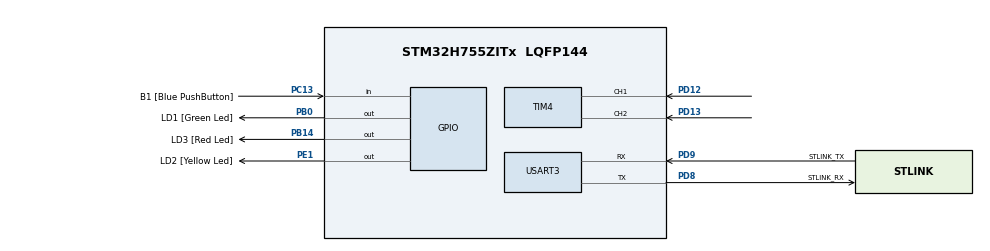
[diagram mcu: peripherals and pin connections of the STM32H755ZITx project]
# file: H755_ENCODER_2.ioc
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CortexM4.IPs=FATFS_M4\:I,FREERTOS_M4\:I,IWDG2\:I,RCC,WWDG2\:I,DMA,BDMA,MDMA,NVIC2\:I,ETH,USART3,DEBUG,USB_DEVICE_M4\:I,USB_HOST_M4\:I,PDM2PCM_M4\:I,PWR,RESMGR_UTILITY,SYS_M4\:I,CORTEX_M4\:I,OPENAMP_M4\:I,VREFBUF,GPIO
CortexM7.IPs=FATFS_M7\:I,FREERTOS_M7\:I,IWDG1\:I,RCC\:I,WWDG1\:I,DMA\:I,BDMA\:I,MDMA\:I,NVIC1\:I,ETH\:I,USART3\:I,USB_OTG_FS\:I,SYS\:I,CORTEX_M7\:I,DEBUG\:I,USB_DEVICE_M7\:I,USB_HOST_M7\:I,PDM2PCM_M7\:I,PWR\:I,RESMGR_UTILITY\:I,OPENAMP_M7\:I,VREFBUF\:I,GPIO\:I,TIM4\:I
Mcu.Family=STM32H7
Mcu.Name=STM32H755ZITx
Mcu.Package=LQFP144
NVIC1.PriorityGroup=NVIC_PRIORITYGROUP_4
NVIC1.TIM4_IRQn=true\:0\:0\:false\:false\:true\:true\:true\:true
NVIC2.PriorityGroup=NVIC_PRIORITYGROUP_4
PB0.GPIO_Label=LD1 [Green Led]
PB0.PinAttribute=Free
PB0.Signal=GPIO_Output
PB14.GPIO_Label=LD3 [Red Led]
PB14.PinAttribute=Free
PB14.Signal=GPIO_Output
PC13.GPIO_Label=B1 [Blue PushButton]
PC13.PinAttribute=Free
PC13.Signal=GPIO_Input
PC14-OSC32_IN\ (OSC32_IN).Mode=LSE-External-Oscillator
PC14-OSC32_IN\ (OSC32_IN).PinAttribute=CortexM7
PC14-OSC32_IN\ (OSC32_IN).Signal=RCC_OSC32_IN
PC15-OSC32_OUT\ (OSC32_OUT).Mode=LSE-External-Oscillator
PC15-OSC32_OUT\ (OSC32_OUT).PinAttribute=CortexM7
PC15-OSC32_OUT\ (OSC32_OUT).Signal=RCC_OSC32_OUT
PD12.PinAttribute=CortexM7
PD12.Signal=S_TIM4_CH1
PD13.PinAttribute=CortexM7
PD13.Signal=S_TIM4_CH2
PD8.GPIO_Label=STLINK_RX
PD8.Mode=Asynchronous
PD8.PinAttribute=CortexM7
PD8.Signal=USART3_TX
PD9.GPIO_Label=STLINK_TX
PD9.Mode=Asynchronous
PD9.PinAttribute=CortexM7
PD9.Signal=USART3_RX
PE1.GPIO_Label=LD2 [Yellow Led]
PE1.PinAttribute=Free
PE1.Signal=GPIO_Output
PH0-OSC_IN\ (PH0).Mode=HSE-External-Clock-Source
PH0-OSC_IN\ (PH0).PinAttribute=CortexM7
PH0-OSC_IN\ (PH0).Signal=RCC_OSC_IN
ProjectManager.HeapSize=M4-0x200,M7-0x200
ProjectManager.StackSize=M4-0x400,M7-0x400
ProjectManager.TargetToolchain=STM32CubeIDE
RCC.ADCFreq_Value=16125000
RCC.APB1Freq_Value=64000000
RCC.APB2Freq_Value=64000000
RCC.APB3Freq_Value=64000000
RCC.APB4Freq_Value=64000000
RCC.CortexFreq_Value=64000000
RCC.DIVM1=1
RCC.DIVN1=24
RCC.DIVQ1=4
RCC.HCLKFreq_Value=64000000
RCC.HSE_VALUE=8000000
RCC.PLL2FRACN=0
RCC.PLL3FRACN=0
RCC.PLLFRACN=0
RCC.PLLSourceVirtual=RCC_PLLSOURCE_HSE
RCC.PWR_Regulator_Voltage_Scale=PWR_REGULATOR_VOLTAGE_SCALE2
RCC.SYSCLKFreq_VALUE=64000000
RCC.SupplySource=PWR_DIRECT_SMPS_SUPPLY
RCC.USBFreq_Value=48000000
SH.S_TIM4_CH1.0=TIM4_CH1,Encoder_Interface
SH.S_TIM4_CH2.0=TIM4_CH2,Encoder_Interface
TIM4.EncoderMode=TIM_ENCODERMODE_TI12
TIM4.IC1Filter=10
TIM4.IC1Polarity=TIM_ICPOLARITY_FALLING
TIM4.IC2Filter=10
TIM4.IC2Polarity=TIM_ICPOLARITY_FALLING
USART3.VirtualMode-Asynchronous=VM_ASYNC
VP_SYS_M4_VS_Systick.Mode=SysTick
board=NUCLEO-H755ZI-Q

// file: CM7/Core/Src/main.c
/* USER CODE BEGIN Header */
/**
  ******************************************************************************
  * @file           : main.c
  * @brief          : Main program body
  ******************************************************************************
  * @attention
  *
  * Copyright (c) 2023 STMicroelectronics.
  * All rights reserved.
  *
  * This software is licensed under terms that can be found in the LICENSE file
  * in the root directory of this software component.
  * If no LICENSE file comes with this software, it is provided AS-IS.
  *
  ******************************************************************************
  */
/* USER CODE END Header */
#include "main.h"

/* USER CODE BEGIN Includes */
#include "myprintf.h"
/* USER CODE END Includes */

/* USER CODE BEGIN PD */

#ifndef HSEM_ID_0
#define HSEM_ID_0 (0U) /* HW semaphore 0*/
#endif
/* USER CODE END PD */

TIM_HandleTypeDef htim4;

UART_HandleTypeDef huart3;

void SystemClock_Config(void);
static void MX_GPIO_Init(void);
static void MX_USART3_UART_Init(void);
static void MX_TIM4_Init(void);

/* USER CODE BEGIN 0 */

uint32_t timer_counter = 0;
int16_t counter = 0;
void HAL_TIM_IC_CaptureCallback(TIM_HandleTypeDef *htim){
	timer_counter = __HAL_TIM_GET_COUNTER(&htim4);
	counter = (int16_t)timer_counter;
}
/* USER CODE END 0 */

int main(void)
{
/* USER CODE BEGIN Boot_Mode_Sequence_0 */
  int32_t timeout;
/* USER CODE END Boot_Mode_Sequence_0 */

/* USER CODE BEGIN Boot_Mode_Sequence_1 */
  /* Wait until CPU2 boots and enters in stop mode or timeout*/
  timeout = 0xFFFF;
  while((__HAL_RCC_GET_FLAG(RCC_FLAG_D2CKRDY) != RESET) && (timeout-- > 0));
  if ( timeout < 0 )
  {
  Error_Handler();
  }
/* USER CODE END Boot_Mode_Sequence_1 */
  /* MCU Configuration--------------------------------------------------------*/

  /* Reset of all peripherals, Initializes the Flash interface and the Systick. */
  HAL_Init();

  /* Configure the system clock */
  SystemClock_Config();
/* USER CODE BEGIN Boot_Mode_Sequence_2 */
/* When system initialization is finished, Cortex-M7 will release Cortex-M4 by means of
HSEM notification */
/*HW semaphore Clock enable*/
__HAL_RCC_HSEM_CLK_ENABLE();
/*Take HSEM */
HAL_HSEM_FastTake(HSEM_ID_0);
/*Release HSEM in order to notify the CPU2(CM4)*/
HAL_HSEM_Release(HSEM_ID_0,0);
/* wait until CPU2 wakes up from stop mode */
timeout = 0xFFFF;
while((__HAL_RCC_GET_FLAG(RCC_FLAG_D2CKRDY) == RESET) && (timeout-- > 0));
if ( timeout < 0 )
{
Error_Handler();
}
/* USER CODE END Boot_Mode_Sequence_2 */

  /* Initialize all configured peripherals */
  MX_GPIO_Init();
  MX_USART3_UART_Init();
  MX_TIM4_Init();

  /* Infinite loop */
  while (1)
  {

    /* USER CODE BEGIN 3 */
	  //1100 ticks per turn approximately
	  //Diameter 62mm
	  //Circumference 195mm
	  printf("%f %d \r\n", ((float)timer_counter/1100)*19.5, counter);

  }
  /* USER CODE END 3 */
}

void SystemClock_Config(void)
{
  RCC_OscInitTypeDef RCC_OscInitStruct = {0};
  RCC_ClkInitTypeDef RCC_ClkInitStruct = {0};

  /** Supply configuration update enable
  */
  HAL_PWREx_ConfigSupply(PWR_DIRECT_SMPS_SUPPLY);

  /** Configure the main internal regulator output voltage
  */
  __HAL_PWR_VOLTAGESCALING_CONFIG(PWR_REGULATOR_VOLTAGE_SCALE2);

  while(!__HAL_PWR_GET_FLAG(PWR_FLAG_VOSRDY)) {}

  /** Initializes the RCC Oscillators according to the specified parameters
  * in the RCC_OscInitTypeDef structure.
  */
  RCC_OscInitStruct.OscillatorType = RCC_OSCILLATORTYPE_HSI;
  RCC_OscInitStruct.HSIState = RCC_HSI_DIV1;
  RCC_OscInitStruct.HSICalibrationValue = RCC_HSICALIBRATION_DEFAULT;
  RCC_OscInitStruct.PLL.PLLState = RCC_PLL_NONE;
  if (HAL_RCC_OscConfig(&RCC_OscInitStruct) != HAL_OK)
  {
    Error_Handler();
  }

  /** Initializes the CPU, AHB and APB buses clocks
  */
  RCC_ClkInitStruct.ClockType = RCC_CLOCKTYPE_HCLK|RCC_CLOCKTYPE_SYSCLK
                              |RCC_CLOCKTYPE_PCLK1|RCC_CLOCKTYPE_PCLK2
                              |RCC_CLOCKTYPE_D3PCLK1|RCC_CLOCKTYPE_D1PCLK1;
  RCC_ClkInitStruct.SYSCLKSource = RCC_SYSCLKSOURCE_HSI;
  RCC_ClkInitStruct.SYSCLKDivider = RCC_SYSCLK_DIV1;
  RCC_ClkInitStruct.AHBCLKDivider = RCC_HCLK_DIV1;
  RCC_ClkInitStruct.APB3CLKDivider = RCC_APB3_DIV1;
  RCC_ClkInitStruct.APB1CLKDivider = RCC_APB1_DIV1;
  RCC_ClkInitStruct.APB2CLKDivider = RCC_APB2_DIV1;
  RCC_ClkInitStruct.APB4CLKDivider = RCC_APB4_DIV1;

  if (HAL_RCC_ClockConfig(&RCC_ClkInitStruct, FLASH_LATENCY_1) != HAL_OK)
  {
    Error_Handler();
  }
}

static void MX_TIM4_Init(void)
{

  TIM_Encoder_InitTypeDef sConfig = {0};
  TIM_MasterConfigTypeDef sMasterConfig = {0};

  htim4.Instance = TIM4;
  htim4.Init.Prescaler = 0;
  htim4.Init.CounterMode = TIM_COUNTERMODE_UP;
  htim4.Init.Period = 65535;
  htim4.Init.ClockDivision = TIM_CLOCKDIVISION_DIV1;
  htim4.Init.AutoReloadPreload = TIM_AUTORELOAD_PRELOAD_DISABLE;
  sConfig.EncoderMode = TIM_ENCODERMODE_TI12;
  sConfig.IC1Polarity = TIM_ICPOLARITY_FALLING;
  sConfig.IC1Selection = TIM_ICSELECTION_DIRECTTI;
  sConfig.IC1Prescaler = TIM_ICPSC_DIV1;
  sConfig.IC1Filter = 10;
  sConfig.IC2Polarity = TIM_ICPOLARITY_FALLING;
  sConfig.IC2Selection = TIM_ICSELECTION_DIRECTTI;
  sConfig.IC2Prescaler = TIM_ICPSC_DIV1;
  sConfig.IC2Filter = 10;
  if (HAL_TIM_Encoder_Init(&htim4, &sConfig) != HAL_OK)
  {
    Error_Handler();
  }
  sMasterConfig.MasterOutputTrigger = TIM_TRGO_RESET;
  sMasterConfig.MasterSlaveMode = TIM_MASTERSLAVEMODE_DISABLE;
  if (HAL_TIMEx_MasterConfigSynchronization(&htim4, &sMasterConfig) != HAL_OK)
  {
    Error_Handler();
  }
  /* USER CODE BEGIN TIM4_Init 2 */
  HAL_TIM_Encoder_Start_IT(&htim4,TIM_CHANNEL_ALL);
  /* USER CODE END TIM4_Init 2 */

}

static void MX_USART3_UART_Init(void)
{

  huart3.Instance = USART3;
  huart3.Init.BaudRate = 115200;
  huart3.Init.WordLength = UART_WORDLENGTH_8B;
  huart3.Init.StopBits = UART_STOPBITS_1;
  huart3.Init.Parity = UART_PARITY_NONE;
  huart3.Init.Mode = UART_MODE_TX_RX;
  huart3.Init.HwFlowCtl = UART_HWCONTROL_NONE;
  huart3.Init.OverSampling = UART_OVERSAMPLING_16;
  huart3.Init.OneBitSampling = UART_ONE_BIT_SAMPLE_DISABLE;
  huart3.Init.ClockPrescaler = UART_PRESCALER_DIV1;
  huart3.AdvancedInit.AdvFeatureInit = UART_ADVFEATURE_NO_INIT;
  if (HAL_UART_Init(&huart3) != HAL_OK)
  {
    Error_Handler();
  }
  if (HAL_UARTEx_SetTxFifoThreshold(&huart3, UART_TXFIFO_THRESHOLD_1_8) != HAL_OK)
  {
    Error_Handler();
  }
  if (HAL_UARTEx_SetRxFifoThreshold(&huart3, UART_RXFIFO_THRESHOLD_1_8) != HAL_OK)
  {
    Error_Handler();
  }
  if (HAL_UARTEx_DisableFifoMode(&huart3) != HAL_OK)
  {
    Error_Handler();
  }

}

static void MX_GPIO_Init(void)
{

  /* GPIO Ports Clock Enable */
  __HAL_RCC_GPIOC_CLK_ENABLE();
  __HAL_RCC_GPIOH_CLK_ENABLE();
  __HAL_RCC_GPIOD_CLK_ENABLE();

}

void Error_Handler(void)
{
  __disable_irq();
  while (1)
  {
  }
}
